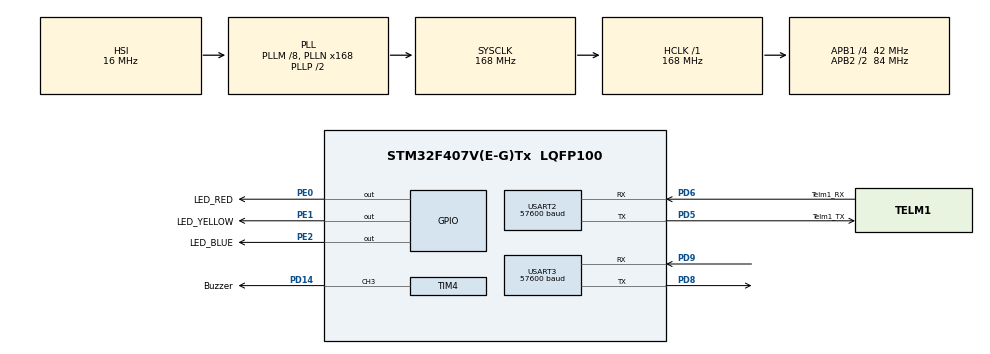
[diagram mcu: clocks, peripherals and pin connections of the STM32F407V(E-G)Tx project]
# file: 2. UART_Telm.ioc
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Mcu.Family=STM32F4
Mcu.Name=STM32F407V(E-G)Tx
Mcu.Package=LQFP100
NVIC.PriorityGroup=NVIC_PRIORITYGROUP_4
NVIC.USART2_IRQn=true\:0\:0\:false\:false\:true\:true\:true\:true
NVIC.USART3_IRQn=true\:0\:0\:false\:false\:true\:true\:true\:true
PD11.Signal=USART3_CTS
PD12.Signal=USART3_RTS
PD14.GPIO_Label=Buzzer
PD14.Signal=S_TIM4_CH3
PD3.Signal=USART2_CTS
PD4.Signal=USART2_RTS
PD5.GPIO_Label=Telm1_TX
PD5.Mode=Asynchronous
PD5.Signal=USART2_TX
PD6.GPIO_Label=Telm1_RX
PD6.Mode=Asynchronous
PD6.Signal=USART2_RX
PD8.Mode=Asynchronous
PD8.Signal=USART3_TX
PD9.Mode=Asynchronous
PD9.Signal=USART3_RX
PE0.GPIO_Label=LED_RED
PE0.Signal=GPIO_Output
PE1.GPIO_Label=LED_YELLOW
PE1.Signal=GPIO_Output
PE2.GPIO_Label=LED_BLUE
PE2.Signal=GPIO_Output
PH0-OSC_IN.Mode=HSE-External-Oscillator
PH0-OSC_IN.Signal=RCC_OSC_IN
PH1-OSC_OUT.Mode=HSE-External-Oscillator
PH1-OSC_OUT.Signal=RCC_OSC_OUT
ProjectManager.HeapSize=0x200
ProjectManager.StackSize=0x400
ProjectManager.TargetToolchain=STM32CubeIDE
RCC.48MHZClocksFreq_Value=84000000
RCC.AHBFreq_Value=168000000
RCC.APB1CLKDivider=RCC_HCLK_DIV4
RCC.APB1Freq_Value=42000000
RCC.APB1TimFreq_Value=84000000
RCC.APB2CLKDivider=RCC_HCLK_DIV2
RCC.APB2Freq_Value=84000000
RCC.APB2TimFreq_Value=168000000
RCC.CortexFreq_Value=168000000
RCC.HCLKFreq_Value=168000000
RCC.HSE_VALUE=25000000
RCC.HSI_VALUE=16000000
RCC.LSE_VALUE=32768
RCC.PLLM=8
RCC.PLLN=168
RCC.SYSCLKFreq_VALUE=168000000
RCC.SYSCLKSource=RCC_SYSCLKSOURCE_PLLCLK
RCC.VCOOutputFreq_Value=336000000
SH.S_TIM4_CH3.0=TIM4_CH3,PWM Generation3 CH3
TIM4.Channel-PWM\ Generation3\ CH3=TIM_CHANNEL_3
TIM4.Period=64220-1
TIM4.Prescaler=5-1
TIM4.Pulse-PWM\ Generation3\ CH3=0
USART2.BaudRate=57600
USART2.VirtualMode=VM_ASYNC
USART3.BaudRate=57600
USART3.VirtualMode=VM_ASYNC
VP_TIM4_VS_ClockSourceINT.Mode=Internal
board=custom

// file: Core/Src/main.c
/* USER CODE BEGIN Header */
/**
  ******************************************************************************
  * @file           : main.c
  * @brief          : Main program body
  ******************************************************************************
  * @attention
  *
  * Copyright (c) 2025 STMicroelectronics.
  * All rights reserved.
  *
  * This software is licensed under terms that can be found in the LICENSE file
  * in the root directory of this software component.
  * If no LICENSE file comes with this software, it is provided AS-IS.
  *
  ******************************************************************************
  */
/* USER CODE END Header */
#include "main.h"

/* USER CODE BEGIN Includes */
#include "FC_Buzzer.h"
/* USER CODE END Includes */

/* USER CODE BEGIN PTD */
int _write(int file, char *p, int len)
{
	for(int i=0; i<len; i++)
	{
		LL_USART_TransmitData8(USART2, *(p+i));
		HAL_Delay(1);
	}
	return len;
}

/* USER CODE END PTD */

/* USER CODE BEGIN PV */
extern uint8_t uart2_rx_flag;
extern uint8_t uart2_rx_data;
/* USER CODE END PV */

void SystemClock_Config(void);
static void MX_GPIO_Init(void);
static void MX_TIM4_Init(void);
static void MX_USART2_UART_Init(void);
static void MX_USART3_UART_Init(void);

int main(void)
{

  /* MCU Configuration--------------------------------------------------------*/

  /* Reset of all peripherals, Initializes the Flash interface and the Systick. */
  HAL_Init();

  /* Configure the system clock */
  SystemClock_Config();

  /* Initialize all configured peripherals */
  MX_GPIO_Init();
  MX_TIM4_Init();
  MX_USART2_UART_Init();
  MX_USART3_UART_Init();
  /* USER CODE BEGIN 2 */

  // interrupt when finished receiving
  LL_TIM_EnableCounter(TIM4);
  BuzzerPlayInit();

  LL_USART_EnableIT_RXNE(USART2);

  /* USER CODE END 2 */

  /* Infinite loop */
  /* USER CODE BEGIN WHILE */
  while (1)
  {
	  if(uart2_rx_flag == 1)
	  {
		  uart2_rx_flag = 0;
		  LL_USART_TransmitData8(USART2, uart2_rx_data);
	  }

    /* USER CODE END WHILE */

  }
}

void SystemClock_Config(void)
{
  RCC_OscInitTypeDef RCC_OscInitStruct = {0};
  RCC_ClkInitTypeDef RCC_ClkInitStruct = {0};

  /** Configure the main internal regulator output voltage
  */
  __HAL_RCC_PWR_CLK_ENABLE();
  __HAL_PWR_VOLTAGESCALING_CONFIG(PWR_REGULATOR_VOLTAGE_SCALE1);

  /** Initializes the RCC Oscillators according to the specified parameters
  * in the RCC_OscInitTypeDef structure.
  */
  RCC_OscInitStruct.OscillatorType = RCC_OSCILLATORTYPE_HSI;
  RCC_OscInitStruct.HSIState = RCC_HSI_ON;
  RCC_OscInitStruct.HSICalibrationValue = RCC_HSICALIBRATION_DEFAULT;
  RCC_OscInitStruct.PLL.PLLState = RCC_PLL_ON;
  RCC_OscInitStruct.PLL.PLLSource = RCC_PLLSOURCE_HSI;
  RCC_OscInitStruct.PLL.PLLM = 8;
  RCC_OscInitStruct.PLL.PLLN = 168;
  RCC_OscInitStruct.PLL.PLLP = RCC_PLLP_DIV2;
  RCC_OscInitStruct.PLL.PLLQ = 4;
  if (HAL_RCC_OscConfig(&RCC_OscInitStruct) != HAL_OK)
  {
    Error_Handler();
  }

  /** Initializes the CPU, AHB and APB buses clocks
  */
  RCC_ClkInitStruct.ClockType = RCC_CLOCKTYPE_HCLK|RCC_CLOCKTYPE_SYSCLK
                              |RCC_CLOCKTYPE_PCLK1|RCC_CLOCKTYPE_PCLK2;
  RCC_ClkInitStruct.SYSCLKSource = RCC_SYSCLKSOURCE_PLLCLK;
  RCC_ClkInitStruct.AHBCLKDivider = RCC_SYSCLK_DIV1;
  RCC_ClkInitStruct.APB1CLKDivider = RCC_HCLK_DIV4;
  RCC_ClkInitStruct.APB2CLKDivider = RCC_HCLK_DIV2;

  if (HAL_RCC_ClockConfig(&RCC_ClkInitStruct, FLASH_LATENCY_5) != HAL_OK)
  {
    Error_Handler();
  }
}

static void MX_TIM4_Init(void)
{

  LL_TIM_InitTypeDef TIM_InitStruct = {0};
  LL_TIM_OC_InitTypeDef TIM_OC_InitStruct = {0};

  LL_GPIO_InitTypeDef GPIO_InitStruct = {0};

  /* Peripheral clock enable */
  LL_APB1_GRP1_EnableClock(LL_APB1_GRP1_PERIPH_TIM4);

  TIM_InitStruct.Prescaler = LL_TIM_IC_FILTER_FDIV2_N8-LL_TIM_IC_FILTER_FDIV1_N2;
  TIM_InitStruct.CounterMode = LL_TIM_COUNTERMODE_UP;
  TIM_InitStruct.Autoreload = 64220-LL_TIM_IC_FILTER_FDIV1_N2;
  TIM_InitStruct.ClockDivision = LL_TIM_CLOCKDIVISION_DIV1;
  LL_TIM_Init(TIM4, &TIM_InitStruct);
  LL_TIM_DisableARRPreload(TIM4);
  LL_TIM_SetClockSource(TIM4, LL_TIM_CLOCKSOURCE_INTERNAL);
  LL_TIM_OC_EnablePreload(TIM4, LL_TIM_CHANNEL_CH3);
  TIM_OC_InitStruct.OCMode = LL_TIM_OCMODE_PWM1;
  TIM_OC_InitStruct.OCState = LL_TIM_OCSTATE_DISABLE;
  TIM_OC_InitStruct.OCNState = LL_TIM_OCSTATE_DISABLE;
  TIM_OC_InitStruct.CompareValue = 0;
  TIM_OC_InitStruct.OCPolarity = LL_TIM_OCPOLARITY_HIGH;
  LL_TIM_OC_Init(TIM4, LL_TIM_CHANNEL_CH3, &TIM_OC_InitStruct);
  LL_TIM_OC_DisableFast(TIM4, LL_TIM_CHANNEL_CH3);
  LL_TIM_SetTriggerOutput(TIM4, LL_TIM_TRGO_RESET);
  LL_TIM_DisableMasterSlaveMode(TIM4);
  LL_AHB1_GRP1_EnableClock(LL_AHB1_GRP1_PERIPH_GPIOD);
  /**TIM4 GPIO Configuration
  PD14   ------> TIM4_CH3
  */
  GPIO_InitStruct.Pin = LL_GPIO_PIN_14;
  GPIO_InitStruct.Mode = LL_GPIO_MODE_ALTERNATE;
  GPIO_InitStruct.Speed = LL_GPIO_SPEED_FREQ_LOW;
  GPIO_InitStruct.OutputType = LL_GPIO_OUTPUT_PUSHPULL;
  GPIO_InitStruct.Pull = LL_GPIO_PULL_NO;
  GPIO_InitStruct.Alternate = LL_GPIO_AF_2;
  LL_GPIO_Init(GPIOD, &GPIO_InitStruct);

}

static void MX_USART2_UART_Init(void)
{

  LL_USART_InitTypeDef USART_InitStruct = {0};

  LL_GPIO_InitTypeDef GPIO_InitStruct = {0};

  /* Peripheral clock enable */
  LL_APB1_GRP1_EnableClock(LL_APB1_GRP1_PERIPH_USART2);

  LL_AHB1_GRP1_EnableClock(LL_AHB1_GRP1_PERIPH_GPIOD);
  /**USART2 GPIO Configuration
  PD3   ------> USART2_CTS
  PD4   ------> USART2_RTS
  PD5   ------> USART2_TX
  PD6   ------> USART2_RX
  */
  GPIO_InitStruct.Pin = LL_GPIO_PIN_3|LL_GPIO_PIN_4|LL_GPIO_PIN_5|LL_GPIO_PIN_6;
  GPIO_InitStruct.Mode = LL_GPIO_MODE_ALTERNATE;
  GPIO_InitStruct.Speed = LL_GPIO_SPEED_FREQ_VERY_HIGH;
  GPIO_InitStruct.OutputType = LL_GPIO_OUTPUT_PUSHPULL;
  GPIO_InitStruct.Pull = LL_GPIO_PULL_NO;
  GPIO_InitStruct.Alternate = LL_GPIO_AF_7;
  LL_GPIO_Init(GPIOD, &GPIO_InitStruct);

  /* USART2 interrupt Init */
  NVIC_SetPriority(USART2_IRQn, NVIC_EncodePriority(NVIC_GetPriorityGrouping(),0, 0));
  NVIC_EnableIRQ(USART2_IRQn);

  USART_InitStruct.BaudRate = 57600;
  USART_InitStruct.DataWidth = LL_USART_DATAWIDTH_8B;
  USART_InitStruct.StopBits = LL_USART_STOPBITS_1;
  USART_InitStruct.Parity = LL_USART_PARITY_NONE;
  USART_InitStruct.TransferDirection = LL_USART_DIRECTION_TX_RX;
  USART_InitStruct.HardwareFlowControl = LL_USART_HWCONTROL_NONE;
  USART_InitStruct.OverSampling = LL_USART_OVERSAMPLING_16;
  LL_USART_Init(USART2, &USART_InitStruct);
  LL_USART_ConfigAsyncMode(USART2);
  LL_USART_Enable(USART2);

}

static void MX_USART3_UART_Init(void)
{

  LL_USART_InitTypeDef USART_InitStruct = {0};

  LL_GPIO_InitTypeDef GPIO_InitStruct = {0};

  /* Peripheral clock enable */
  LL_APB1_GRP1_EnableClock(LL_APB1_GRP1_PERIPH_USART3);

  LL_AHB1_GRP1_EnableClock(LL_AHB1_GRP1_PERIPH_GPIOD);
  /**USART3 GPIO Configuration
  PD8   ------> USART3_TX
  PD9   ------> USART3_RX
  PD11   ------> USART3_CTS
  PD12   ------> USART3_RTS
  */
  GPIO_InitStruct.Pin = LL_GPIO_PIN_8|LL_GPIO_PIN_9|LL_GPIO_PIN_11|LL_GPIO_PIN_12;
  GPIO_InitStruct.Mode = LL_GPIO_MODE_ALTERNATE;
  GPIO_InitStruct.Speed = LL_GPIO_SPEED_FREQ_VERY_HIGH;
  GPIO_InitStruct.OutputType = LL_GPIO_OUTPUT_PUSHPULL;
  GPIO_InitStruct.Pull = LL_GPIO_PULL_NO;
  GPIO_InitStruct.Alternate = LL_GPIO_AF_7;
  LL_GPIO_Init(GPIOD, &GPIO_InitStruct);

  /* USART3 interrupt Init */
  NVIC_SetPriority(USART3_IRQn, NVIC_EncodePriority(NVIC_GetPriorityGrouping(),0, 0));
  NVIC_EnableIRQ(USART3_IRQn);

  USART_InitStruct.BaudRate = 57600;
  USART_InitStruct.DataWidth = LL_USART_DATAWIDTH_8B;
  USART_InitStruct.StopBits = LL_USART_STOPBITS_1;
  USART_InitStruct.Parity = LL_USART_PARITY_NONE;
  USART_InitStruct.TransferDirection = LL_USART_DIRECTION_TX_RX;
  USART_InitStruct.HardwareFlowControl = LL_USART_HWCONTROL_NONE;
  USART_InitStruct.OverSampling = LL_USART_OVERSAMPLING_16;
  LL_USART_Init(USART3, &USART_InitStruct);
  LL_USART_ConfigAsyncMode(USART3);
  LL_USART_Enable(USART3);

}

static void MX_GPIO_Init(void)
{
  GPIO_InitTypeDef GPIO_InitStruct = {0};

  /* GPIO Ports Clock Enable */
  __HAL_RCC_GPIOE_CLK_ENABLE();
  __HAL_RCC_GPIOH_CLK_ENABLE();
  __HAL_RCC_GPIOD_CLK_ENABLE();

  /*Configure GPIO pin Output Level */
  HAL_GPIO_WritePin(GPIOE, LED_BLUE_Pin|LED_RED_Pin|LED_YELLOW_Pin, GPIO_PIN_RESET);

  /*Configure GPIO pins : LED_BLUE_Pin LED_RED_Pin LED_YELLOW_Pin */
  GPIO_InitStruct.Pin = LED_BLUE_Pin|LED_RED_Pin|LED_YELLOW_Pin;
  GPIO_InitStruct.Mode = GPIO_MODE_OUTPUT_PP;
  GPIO_InitStruct.Pull = GPIO_NOPULL;
  GPIO_InitStruct.Speed = GPIO_SPEED_FREQ_LOW;
  HAL_GPIO_Init(GPIOE, &GPIO_InitStruct);

}

void Error_Handler(void)
{
  __disable_irq();
  while (1)
  {
  }
}
